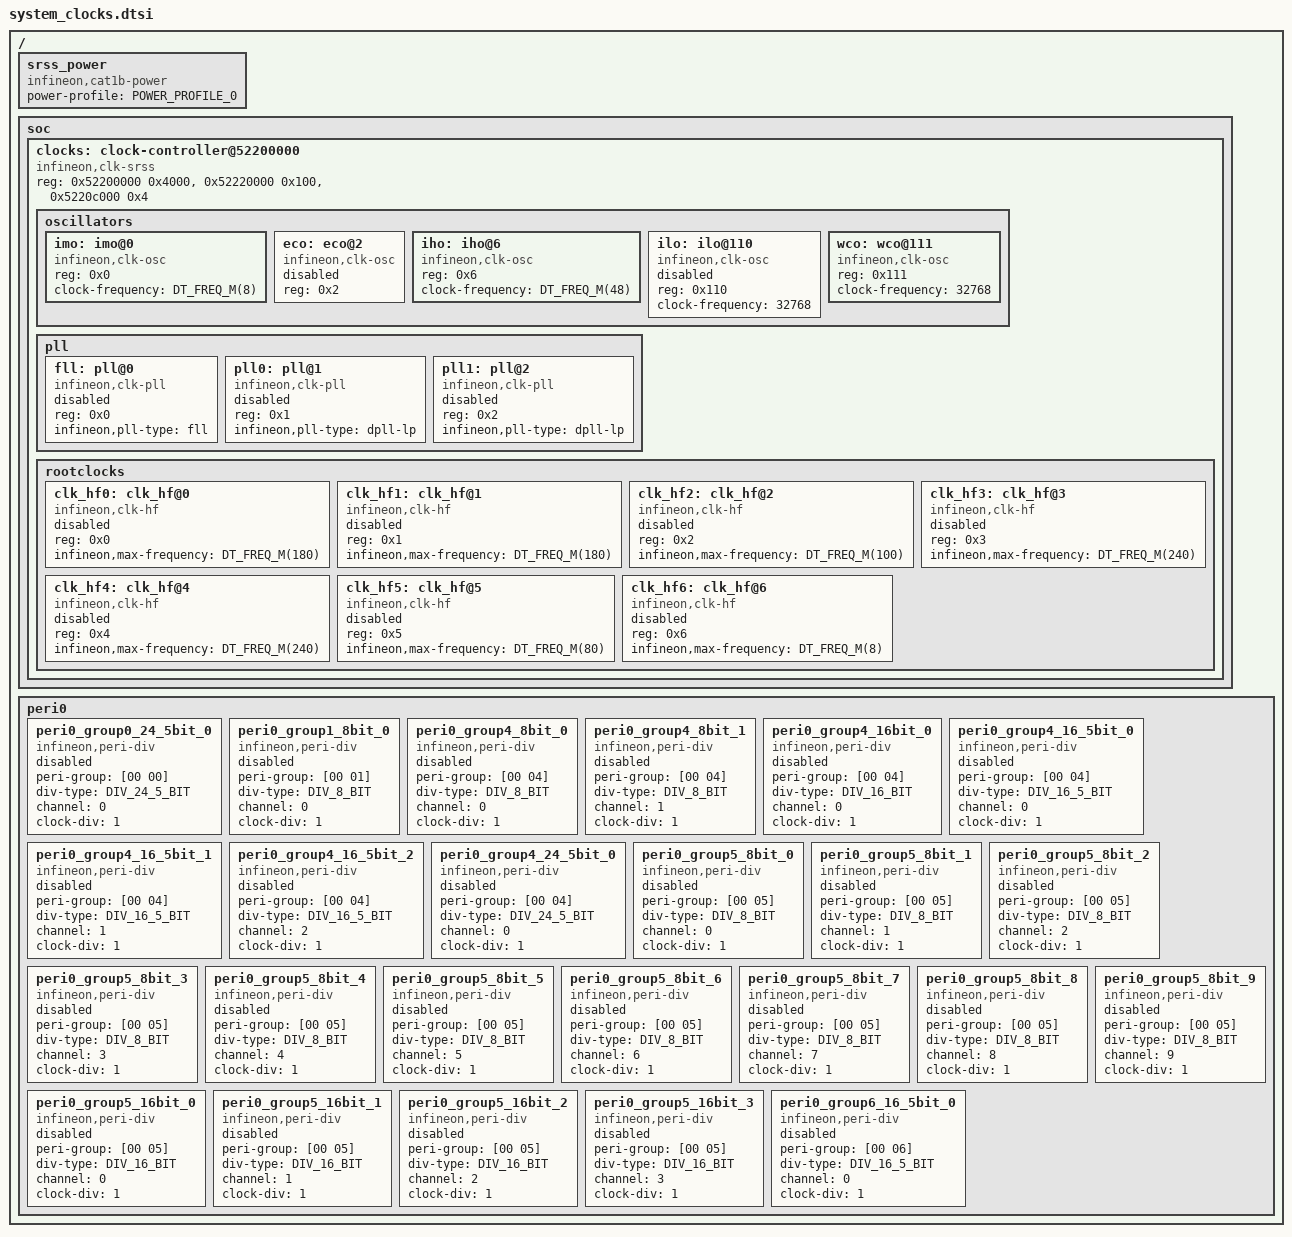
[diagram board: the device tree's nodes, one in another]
/*
 * Copyright (c) 2025 Cypress Semiconductor Corporation (an Infineon company) or
 * an affiliate of Cypress Semiconductor Corporation
 *
 * SPDX-License-Identifier: Apache-2.0
 */

#define DIV_8_BIT    00
#define DIV_16_BIT	 01
#define DIV_16_5_BIT 02
#define DIV_24_5_BIT 03

#include <freq.h>
#include <zephyr/dt-bindings/clock/ifx_clock_source_common.h>
#include <zephyr/dt-bindings/clock/ifx_clock_source_psc3xx.h>

/ {
	srss_power: srss_power {
		compatible = "infineon,cat1b-power";
		#clock-cells = <0>;
		power-profile = "POWER_PROFILE_0";
		status = "okay";
	};

	soc {
		clocks: clock-controller@52200000 {
			compatible = "infineon,clk-srss";
			reg = <0x52200000 0x4000>,
			      <0x52220000 0x100>,
			      <0x5220c000 0x4>;
			reg-names = "srss", "backup", "wdt";

			oscillators {
				#address-cells = <1>;
				#size-cells = <0>;

				imo: imo@0 {
					compatible = "infineon,clk-osc";
					reg = <0x0>;
					#clock-cells = <0>;
					clock-frequency = <DT_FREQ_M(8)>;
					status = "okay";
				};

				eco: eco@2 {
					compatible = "infineon,clk-osc";
					reg = <0x2>;
					#clock-cells = <0>;
					status = "disabled";
				};

				iho: iho@6 {
					compatible = "infineon,clk-osc";
					reg = <0x6>;
					#clock-cells = <0>;
					clock-frequency = <DT_FREQ_M(48)>;
					status = "okay";
				};

				ilo: ilo@110 {
					compatible = "infineon,clk-osc";
					reg = <0x110>;
					#clock-cells = <0>;
					clock-frequency = <32768>;
					status = "disabled";
				};

				wco: wco@111 {
					compatible = "infineon,clk-osc";
					reg = <0x111>;
					#clock-cells = <0>;
					clock-frequency = <32768>;
					status = "okay";
				};
			};

			pll {
				#address-cells = <1>;
				#size-cells = <0>;

				fll: pll@0 {
					compatible = "infineon,clk-pll";
					reg = <0x0>;
					#clock-cells = <0>;
					infineon,pll-type = "fll";
					status = "disabled";
				};

				pll0: pll@1 {
					compatible = "infineon,clk-pll";
					reg = <0x1>;
					#clock-cells = <0>;
					infineon,pll-type = "dpll-lp";
					status = "disabled";
				};

				pll1: pll@2 {
					compatible = "infineon,clk-pll";
					reg = <0x2>;
					#clock-cells = <0>;
					infineon,pll-type = "dpll-lp";
					status = "disabled";
				};
			};

			rootclocks {
				#address-cells = <1>;
				#size-cells = <0>;

				clk_hf0: clk_hf@0 {
					compatible = "infineon,clk-hf";
					reg = <0x0>;
					#clock-cells = <0>;
					infineon,max-frequency =
						<DT_FREQ_M(180)>;
					status = "disabled";
				};

				clk_hf1: clk_hf@1 {
					compatible = "infineon,clk-hf";
					reg = <0x1>;
					#clock-cells = <0>;
					infineon,max-frequency =
						<DT_FREQ_M(180)>;
					status = "disabled";
				};

				clk_hf2: clk_hf@2 {
					compatible = "infineon,clk-hf";
					reg = <0x2>;
					#clock-cells = <0>;
					infineon,max-frequency =
						<DT_FREQ_M(100)>;
					status = "disabled";
				};

				clk_hf3: clk_hf@3 {
					compatible = "infineon,clk-hf";
					reg = <0x3>;
					#clock-cells = <0>;
					infineon,max-frequency =
						<DT_FREQ_M(240)>;
					status = "disabled";
				};

				clk_hf4: clk_hf@4 {
					compatible = "infineon,clk-hf";
					reg = <0x4>;
					#clock-cells = <0>;
					infineon,max-frequency =
						<DT_FREQ_M(240)>;
					status = "disabled";
				};

				clk_hf5: clk_hf@5 {
					compatible = "infineon,clk-hf";
					reg = <0x5>;
					#clock-cells = <0>;
					infineon,max-frequency =
						<DT_FREQ_M(80)>;
					status = "disabled";
				};

				clk_hf6: clk_hf@6 {
					compatible = "infineon,clk-hf";
					reg = <0x6>;
					#clock-cells = <0>;
					infineon,max-frequency = <DT_FREQ_M(8)>;
					status = "disabled";
				};
			};
		};
	};

	peri0: peri0 {
		/* Peripheral 0, Clock Group 0 */
		/* 24.5-bit */
		peri0_group0_24_5bit_0: peri0_group0_24_5bit_0 {
			compatible = "infineon,peri-div";
			#clock-cells = <0>;
			peri-group = [00 00]; /* inst#, group# */
			div-type = <DIV_24_5_BIT>;
			channel = <0>;
			clock-div = <1>;
			status = "disabled";
		};

		/* Peripheral 0, Clock Group 1 */
		/* 8-bit */
		peri0_group1_8bit_0: peri0_group1_8bit_0 {
			compatible = "infineon,peri-div";
			#clock-cells = <0>;
			peri-group = [00 01]; /* inst#, group# */
			div-type = <DIV_8_BIT>;
			channel = <0>;
			clock-div = <1>;
			status = "disabled";
		};

		/* Peripheral 0, Clock Group 4 */
		/* 8-bit */
		peri0_group4_8bit_0: peri0_group4_8bit_0 {
			compatible = "infineon,peri-div";
			#clock-cells = <0>;
			peri-group = [00 04]; /* inst#, group# */
			div-type = <DIV_8_BIT>;
			channel = <0>;
			clock-div = <1>;
			status = "disabled";
		};

		peri0_group4_8bit_1: peri0_group4_8bit_1 {
			compatible = "infineon,peri-div";
			#clock-cells = <0>;
			peri-group = [00 04]; /* inst#, group# */
			div-type = <DIV_8_BIT>;
			channel = <1>;
			clock-div = <1>;
			status = "disabled";
		};

		/* 16-bit */
		peri0_group4_16bit_0: peri0_group4_16bit_0 {
			compatible = "infineon,peri-div";
			#clock-cells = <0>;
			peri-group = [00 04]; /* inst#, group# */
			div-type = <DIV_16_BIT>;
			channel = <0>;
			clock-div = <1>;
			status = "disabled";
		};

		/* 16.5-bit */
		peri0_group4_16_5bit_0: peri0_group4_16_5bit_0 {
			compatible = "infineon,peri-div";
			#clock-cells = <0>;
			peri-group = [00 04]; /* inst#, group# */
			div-type = <DIV_16_5_BIT>;
			channel = <0>;
			clock-div = <1>;
			status = "disabled";
		};

		peri0_group4_16_5bit_1: peri0_group4_16_5bit_1 {
			compatible = "infineon,peri-div";
			#clock-cells = <0>;
			peri-group = [00 04]; /* inst#, group# */
			div-type = <DIV_16_5_BIT>;
			channel = <1>;
			clock-div = <1>;
			status = "disabled";
		};

		peri0_group4_16_5bit_2: peri0_group4_16_5bit_2 {
			compatible = "infineon,peri-div";
			#clock-cells = <0>;
			peri-group = [00 04]; /* inst#, group# */
			div-type = <DIV_16_5_BIT>;
			channel = <2>;
			clock-div = <1>;
			status = "disabled";
		};

		/* 24.5-bit */
		peri0_group4_24_5bit_0: peri0_group4_24_5bit_0 {
			compatible = "infineon,peri-div";
			#clock-cells = <0>;
			peri-group = [00 04]; /* inst#, group# */
			div-type = <DIV_24_5_BIT>;
			channel = <0>;
			clock-div = <1>;
			status = "disabled";
		};

		/* Peripheral 0, Clock Group 5 */
		/* 8-bit */
		peri0_group5_8bit_0: peri0_group5_8bit_0 {
			compatible = "infineon,peri-div";
			#clock-cells = <0>;
			peri-group = [00 05]; /* inst#, group# */
			div-type = <DIV_8_BIT>;
			channel = <0>;
			clock-div = <1>;
			status = "disabled";
		};

		peri0_group5_8bit_1: peri0_group5_8bit_1 {
			compatible = "infineon,peri-div";
			#clock-cells = <0>;
			peri-group = [00 05]; /* inst#, group# */
			div-type = <DIV_8_BIT>;
			channel = <1>;
			clock-div = <1>;
			status = "disabled";
		};

		peri0_group5_8bit_2: peri0_group5_8bit_2 {
			compatible = "infineon,peri-div";
			#clock-cells = <0>;
			peri-group = [00 05]; /* inst#, group# */
			div-type = <DIV_8_BIT>;
			channel = <2>;
			clock-div = <1>;
			status = "disabled";
		};

		peri0_group5_8bit_3: peri0_group5_8bit_3 {
			compatible = "infineon,peri-div";
			#clock-cells = <0>;
			peri-group = [00 05]; /* inst#, group# */
			div-type = <DIV_8_BIT>;
			channel = <3>;
			clock-div = <1>;
			status = "disabled";
		};

		peri0_group5_8bit_4: peri0_group5_8bit_4 {
			compatible = "infineon,peri-div";
			#clock-cells = <0>;
			peri-group = [00 05]; /* inst#, group# */
			div-type = <DIV_8_BIT>;
			channel = <4>;
			clock-div = <1>;
			status = "disabled";
		};

		peri0_group5_8bit_5: peri0_group5_8bit_5 {
			compatible = "infineon,peri-div";
			#clock-cells = <0>;
			peri-group = [00 05]; /* inst#, group# */
			div-type = <DIV_8_BIT>;
			channel = <5>;
			clock-div = <1>;
			status = "disabled";
		};

		peri0_group5_8bit_6: peri0_group5_8bit_6 {
			compatible = "infineon,peri-div";
			#clock-cells = <0>;
			peri-group = [00 05]; /* inst#, group# */
			div-type = <DIV_8_BIT>;
			channel = <6>;
			clock-div = <1>;
			status = "disabled";
		};

		peri0_group5_8bit_7: peri0_group5_8bit_7 {
			compatible = "infineon,peri-div";
			#clock-cells = <0>;
			peri-group = [00 05]; /* inst#, group# */
			div-type = <DIV_8_BIT>;
			channel = <7>;
			clock-div = <1>;
			status = "disabled";
		};

		peri0_group5_8bit_8: peri0_group5_8bit_8 {
			compatible = "infineon,peri-div";
			#clock-cells = <0>;
			peri-group = [00 05]; /* inst#, group# */
			div-type = <DIV_8_BIT>;
			channel = <8>;
			clock-div = <1>;
			status = "disabled";
		};

		peri0_group5_8bit_9: peri0_group5_8bit_9 {
			compatible = "infineon,peri-div";
			#clock-cells = <0>;
			peri-group = [00 05]; /* inst#, group# */
			div-type = <DIV_8_BIT>;
			channel = <9>;
			clock-div = <1>;
			status = "disabled";
		};

		/* 16-bit */
		peri0_group5_16bit_0: peri0_group5_16bit_0 {
			compatible = "infineon,peri-div";
			#clock-cells = <0>;
			peri-group = [00 05]; /* inst#, group# */
			div-type = <DIV_16_BIT>;
			channel = <0>;
			clock-div = <1>;
			status = "disabled";
		};

		peri0_group5_16bit_1: peri0_group5_16bit_1 {
			compatible = "infineon,peri-div";
			#clock-cells = <0>;
			peri-group = [00 05]; /* inst#, group# */
			div-type = <DIV_16_BIT>;
			channel = <1>;
			clock-div = <1>;
			status = "disabled";
		};

		peri0_group5_16bit_2: peri0_group5_16bit_2 {
			compatible = "infineon,peri-div";
			#clock-cells = <0>;
			peri-group = [00 05]; /* inst#, group# */
			div-type = <DIV_16_BIT>;
			channel = <2>;
			clock-div = <1>;
			status = "disabled";
		};

		peri0_group5_16bit_3: peri0_group5_16bit_3 {
			compatible = "infineon,peri-div";
			#clock-cells = <0>;
			peri-group = [00 05]; /* inst#, group# */
			div-type = <DIV_16_BIT>;
			channel = <3>;
			clock-div = <1>;
			status = "disabled";
		};

		/* Peripheral 0, Clock Group 6 */
		/* 16.5-bit */
		peri0_group6_16_5bit_0: peri0_group6_16_5bit_0 {
			compatible = "infineon,peri-div";
			#clock-cells = <0>;
			peri-group = [00 06]; /* inst#, group# */
			div-type = <DIV_16_5_BIT>;
			channel = <0>;
			clock-div = <1>;
			status = "disabled";
		};
	};
};
